# max32570 register map
Vendor: Maxim-Integrated; Series: ARMCM4; File version: 1.0
CPU: CM4 r2p1, little endian, MPU, FPU, 3 interrupt priority bits
Registers are 32-bit, read-write, reset 0x0 unless marked. A register's access mark holds for its fields unless they carry their own. Offsets are from the block's base; [hi:lo] are bit positions; {n}, {i} and the like mark numbered series; 'fields as' and 'values as' point back to an identical list.

## ICC0 — Instruction Cache Controller Registers
Base 0x4002A000
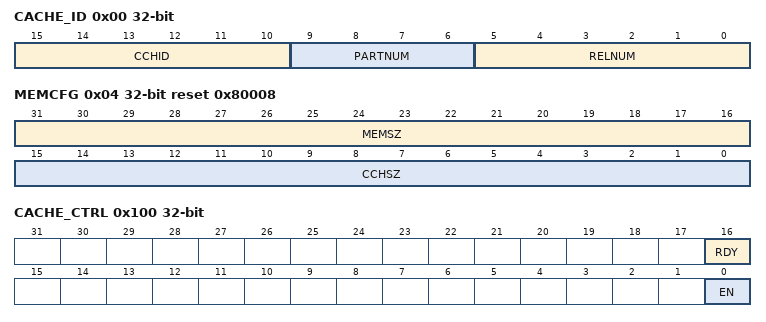
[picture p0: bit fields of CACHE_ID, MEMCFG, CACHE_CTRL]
0x00 CACHE_ID ro
  [15:10] CCHID — Cache ID. This field reflects the value of the C_ID_CACHEID configuration parameter.
  [9:6] PARTNUM — Part Number. This field reflects the value of C_ID_PART_NUMBER configuration parameter.
  [5:0] RELNUM — Release Number. Identifies the RTL release version.
0x04 MEMCFG ro reset 0x80008 — Memory Configuration Register.
  [31:16] MEMSZ — Main Memory Size. Indicates the total size, in units of 128 Kbytes, of code memory accessible to the cache controller.
  [15:0] CCHSZ — Cache Size. Indicates total size in Kbytes of cache.
0x100 CACHE_CTRL — Cache Control and Status Register.
  [16] RDY ro — Cache Ready flag. Cleared by hardware when at any time the cache as a whole is invalidated (including a system reset). When this bit is 0, the cache is effectively in bypass mode (instruction fetches will come from main memory or from the line fill buffer). Set by hardware when the invalidate operation is complete and the cache is ready.
    0=invalid (Not Ready.); 1=ready
  [0] EN — Cache Enable. Controls whether the cache is bypassed or is in use. Changing the state of this bit will cause the instruction cache to be flushed and its contents invalidated.
    0=dis (Cache Bypassed. Instruction data is stored in the line fill buffer but is not written to main cache memory array.); 1=en (Cache Enabled.)
0x700 INVALIDATE — Invalidate All Registers.
  [31:0] INVALID — Invalidate.

## OWM — 1-Wire Master Interface.
Base 0x4003D000
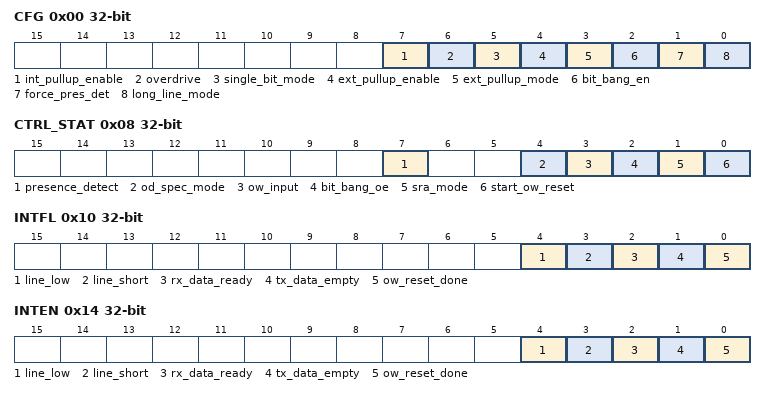
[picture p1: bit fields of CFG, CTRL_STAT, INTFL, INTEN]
0x00 CFG — 1-Wire Master Configuration.
  [7] int_pullup_enable — Enable intenral pullup.
  [6] overdrive — Enables overdrive speed for 1-Wire operations.
  [5] single_bit_mode — Enable Single Bit TX/RX Mode.
  [4] ext_pullup_enable — Enable External Pullup.
  [3] ext_pullup_mode — Provide an extra output control to control an external pullup.
  [2] bit_bang_en — Bit Bang Enable.
  [1] force_pres_det — Force Line During Presence Detect.
  [0] long_line_mode
0x04 CLK_DIV_1US — 1-Wire Master Clock Divisor.
  [7:0] divisor — Clock Divisor for 1Mhz.
0x08 CTRL_STAT — 1-Wire Master Control/Status.
  [7] presence_detect ro — Presence Pulse Detected.
  [4] od_spec_mode ro — Overdrive Spec Mode.
  [3] ow_input ro — OW Input State.
  [2] bit_bang_oe — Bit Bang Output Enable.
  [1] sra_mode
  [0] start_ow_reset
0x0C DATA — 1-Wire Master Data Buffer.
  [7:0] tx_rx — TX/RX Buffer.
0x10 INTFL — 1-Wire Master Interrupt Flags.
  [4] line_low — OW Line Low Detected Interrupt Flag.
  [3] line_short — OW Line Short Detected Interrupt Flag.
  [2] rx_data_ready — RX Data Ready Interrupt Flag
  [1] tx_data_empty — TX Data Empty Interrupt Flag.
  [0] ow_reset_done — OW Reset Sequence Completed.
0x14 INTEN — 1-Wire Master Interrupt Enables.
  [4] line_low write-1-clears — OW Line Low Detected Interrupt Enable.
  [3] line_short write-1-clears — OW Line Short Detected Interrupt Enable.
  [2] rx_data_ready write-1-clears — Rx Data Ready Interrupt Enable.
  [1] tx_data_empty write-1-clears — Tx Data Empty Interrupt Enable.
  [0] ow_reset_done write-1-clears — OW Reset Sequence Completed.

## PTG — Pulse Train Generation
Base 0x4003C000
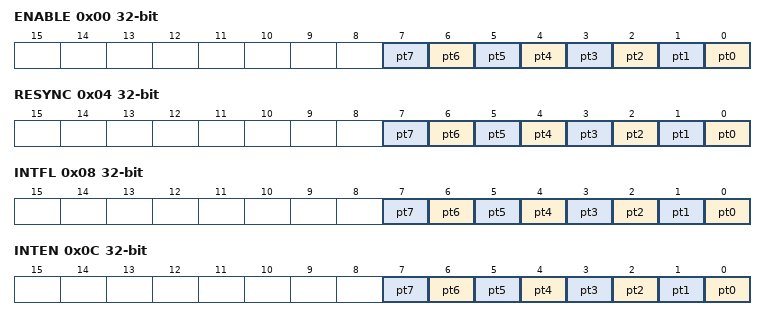
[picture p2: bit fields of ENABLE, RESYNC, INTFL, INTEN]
0x00 ENABLE — Global Enable/Disable Controls for All Pulse Trains
  [n] pt{n} (n=0..7) — Enable/Disable control for PT{n}
0x04 RESYNC — Global Resync (All Pulse Trains) Control
  [n] pt{n} (n=0..7) — Resync control for PT{n}
0x08 INTFL — Pulse Train Interrupt Flags
  [n] pt{n} (n=0..7) — Pulse Train {n} Stopped Interrupt Flag
0x0C INTEN — Pulse Train Interrupt Enable/Disable
  [n] pt{n} (n=0..7) — Pulse Train {n} Stopped Interrupt Enable/Disable
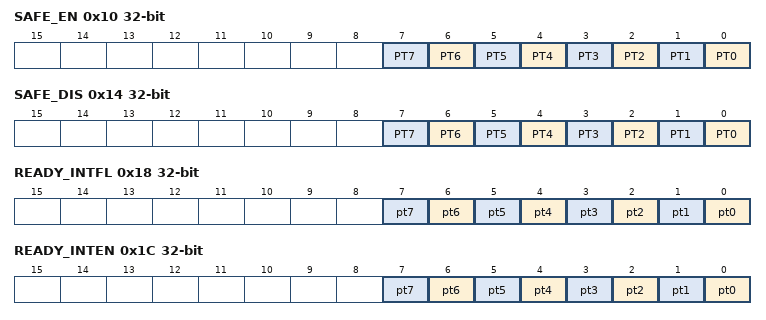
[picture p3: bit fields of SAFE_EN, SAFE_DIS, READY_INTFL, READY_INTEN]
0x10 SAFE_EN wo — Pulse Train Global Safe Enable.
  [n] PT{n} (n=0..7)
0x14 SAFE_DIS wo — Pulse Train Global Safe Disable.
  [n] PT{n} (n=0..7)
0x18 READY_INTFL — Pulse Train Ready Interrupt Flags
  [n] pt{n} (n=0..7) — Pulse Train {n} Stopped Interrupt Flag
0x1C READY_INTEN — Pulse Train Ready Interrupt Enable/Disable
  fields as INTEN
